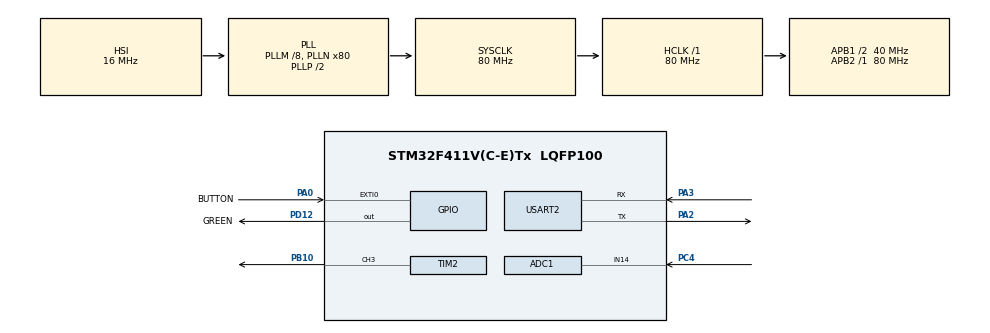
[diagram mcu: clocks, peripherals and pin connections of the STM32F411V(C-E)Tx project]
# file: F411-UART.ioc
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ADC1.Channel-3\#ChannelRegularConversion=ADC_CHANNEL_14
ADC1.ExternalTrigConv=ADC_EXTERNALTRIGCONV_T3_TRGO
ADC1.ExternalTrigConvEdge=ADC_EXTERNALTRIGCONVEDGE_RISINGFALLING
ADC1.NbrOfConversionFlag=1
ADC1.Rank-3\#ChannelRegularConversion=1
ADC1.Resolution=ADC_RESOLUTION_10B
ADC1.SamplingTime-3\#ChannelRegularConversion=ADC_SAMPLETIME_3CYCLES
ADC1.master=1
Dma.ADC1.0.Direction=DMA_PERIPH_TO_MEMORY
Dma.ADC1.0.FIFOMode=DMA_FIFOMODE_DISABLE
Dma.ADC1.0.Instance=DMA2_Stream0
Dma.ADC1.0.MemDataAlignment=DMA_MDATAALIGN_HALFWORD
Dma.ADC1.0.MemInc=DMA_MINC_ENABLE
Dma.ADC1.0.Mode=DMA_CIRCULAR
Dma.ADC1.0.PeriphDataAlignment=DMA_PDATAALIGN_HALFWORD
Dma.ADC1.0.PeriphInc=DMA_PINC_DISABLE
Dma.ADC1.0.Priority=DMA_PRIORITY_LOW
Dma.Request0=ADC1
Mcu.Family=STM32F4
Mcu.Name=STM32F411V(C-E)Tx
Mcu.Package=LQFP100
NVIC.DMA2_Stream0_IRQn=true\:0\:0\:false\:false\:true\:false\:true\:true
NVIC.EXTI0_IRQn=true\:0\:0\:false\:false\:true\:true\:true\:true
NVIC.PriorityGroup=NVIC_PRIORITYGROUP_4
NVIC.RCC_IRQn=true\:0\:0\:false\:false\:true\:true\:false\:true
PA0-WKUP.GPIO_Label=BUTTON
PA0-WKUP.Signal=GPXTI0
PA2.Mode=Asynchronous
PA2.Signal=USART2_TX
PA3.Mode=Asynchronous
PA3.Signal=USART2_RX
PB10.Signal=S_TIM2_CH3
PC4.Signal=ADCx_IN14
PD12.GPIO_Label=GREEN
PD12.Signal=GPIO_Output
PH0\ -\ OSC_IN.Mode=HSE-External-Oscillator
PH0\ -\ OSC_IN.Signal=RCC_OSC_IN
PH1\ -\ OSC_OUT.Mode=HSE-External-Oscillator
PH1\ -\ OSC_OUT.Signal=RCC_OSC_OUT
ProjectManager.HeapSize=0x200
ProjectManager.StackSize=0x400
ProjectManager.TargetToolchain=STM32CubeIDE
RCC.48MHZClocksFreq_Value=40000000
RCC.AHBFreq_Value=80000000
RCC.APB1CLKDivider=RCC_HCLK_DIV2
RCC.APB1Freq_Value=40000000
RCC.APB1TimFreq_Value=80000000
RCC.APB2Freq_Value=80000000
RCC.APB2TimFreq_Value=80000000
RCC.CortexFreq_Value=80000000
RCC.HCLKFreq_Value=80000000
RCC.HSE_VALUE=25000000
RCC.HSI_VALUE=16000000
RCC.LSE_VALUE=32768
RCC.PLLM=8
RCC.PLLN=80
RCC.SYSCLKFreq_VALUE=80000000
RCC.SYSCLKSource=RCC_SYSCLKSOURCE_PLLCLK
RCC.VCOOutputFreq_Value=160000000
SH.ADCx_IN14.0=ADC1_IN14,IN14
SH.S_TIM2_CH3.0=TIM2_CH3,PWM Generation3 CH3
TIM2.Channel-PWM\ Generation3\ CH3=TIM_CHANNEL_3
TIM2.Period=4-1
TIM2.Prescaler=10 -1 
TIM3.Period=1000-1
TIM3.Prescaler=80-1
TIM3.TIM_MasterOutputTrigger=TIM_TRGO_UPDATE
USART2.VirtualMode=VM_ASYNC
VP_TIM2_VS_ClockSourceINT.Mode=Internal
VP_TIM3_VS_ClockSourceINT.Mode=Internal
board=custom

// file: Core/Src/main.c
/* USER CODE BEGIN Header */
/**
  ******************************************************************************
  * @file           : main.c
  * @brief          : Main program body
  ******************************************************************************
  * @attention
  *
  * Copyright (c) 2022 STMicroelectronics.
  * All rights reserved.
  *
  * This software is licensed under terms that can be found in the LICENSE file
  * in the root directory of this software component.
  * If no LICENSE file comes with this software, it is provided AS-IS.
  *
  ******************************************************************************
  */
/* USER CODE END Header */
#include "main.h"
#include "adc.h"
#include "dma.h"
#include "tim.h"
#include "usart.h"
#include "gpio.h"

/* USER CODE BEGIN Includes */
#include <string.h>
#include <stdlib.h>
#include <stdio.h>

#include "gpio.h"
#include "usart.h"
#include "console.h"
/* USER CODE END Includes */

void SystemClock_Config(void);

int main(void)
{

  /* MCU Configuration--------------------------------------------------------*/

  /* Reset of all peripherals, Initializes the Flash interface and the Systick. */
  HAL_Init();

  /* USER CODE BEGIN Init */
  ConsoleInit();
  // Sets the read buf to zero to not wait indefinitely
  setvbuf(stdin, NULL, _IONBF, 0);
  /* USER CODE END Init */

  /* Configure the system clock */
  SystemClock_Config();

  /* Initialize all configured peripherals */
  MX_GPIO_Init();
  MX_DMA_Init();
  MX_USART2_UART_Init();
  MX_ADC1_Init();
  MX_TIM2_Init();
  MX_TIM3_Init();
  /* USER CODE BEGIN 2 */
  HAL_TIM_Base_Start_IT(&htim2);
  HAL_TIM_PWM_Start(&htim2, TIM_CHANNEL_3);
  __HAL_TIM_SET_COMPARE(&htim2, TIM_CHANNEL_3, 2);
  //HAL_TIM_PWM_ConfigChannel(&htim2, &sConfigOC, TIM_CHANNEL_3);
  /* USER CODE END 2 */

  /* Infinite loop */
  /* USER CODE BEGIN WHILE */
  while (1)
  {
     ConsoleProcess();
    /* USER CODE END WHILE */

  }
}

void SystemClock_Config(void)
{
  RCC_OscInitTypeDef RCC_OscInitStruct = {0};
  RCC_ClkInitTypeDef RCC_ClkInitStruct = {0};

  /** Configure the main internal regulator output voltage
  */
  __HAL_RCC_PWR_CLK_ENABLE();
  __HAL_PWR_VOLTAGESCALING_CONFIG(PWR_REGULATOR_VOLTAGE_SCALE1);

  /** Initializes the RCC Oscillators according to the specified parameters
  * in the RCC_OscInitTypeDef structure.
  */
  RCC_OscInitStruct.OscillatorType = RCC_OSCILLATORTYPE_HSI;
  RCC_OscInitStruct.HSIState = RCC_HSI_ON;
  RCC_OscInitStruct.HSICalibrationValue = RCC_HSICALIBRATION_DEFAULT;
  RCC_OscInitStruct.PLL.PLLState = RCC_PLL_ON;
  RCC_OscInitStruct.PLL.PLLSource = RCC_PLLSOURCE_HSI;
  RCC_OscInitStruct.PLL.PLLM = 8;
  RCC_OscInitStruct.PLL.PLLN = 80;
  RCC_OscInitStruct.PLL.PLLP = RCC_PLLP_DIV2;
  RCC_OscInitStruct.PLL.PLLQ = 4;
  if (HAL_RCC_OscConfig(&RCC_OscInitStruct) != HAL_OK)
  {
    Error_Handler();
  }

  /** Initializes the CPU, AHB and APB buses clocks
  */
  RCC_ClkInitStruct.ClockType = RCC_CLOCKTYPE_HCLK|RCC_CLOCKTYPE_SYSCLK
                              |RCC_CLOCKTYPE_PCLK1|RCC_CLOCKTYPE_PCLK2;
  RCC_ClkInitStruct.SYSCLKSource = RCC_SYSCLKSOURCE_PLLCLK;
  RCC_ClkInitStruct.AHBCLKDivider = RCC_SYSCLK_DIV1;
  RCC_ClkInitStruct.APB1CLKDivider = RCC_HCLK_DIV2;
  RCC_ClkInitStruct.APB2CLKDivider = RCC_HCLK_DIV1;

  if (HAL_RCC_ClockConfig(&RCC_ClkInitStruct, FLASH_LATENCY_2) != HAL_OK)
  {
    Error_Handler();
  }
}

void Error_Handler(void)
{
  __disable_irq();
  while (1)
  {
  }
}
